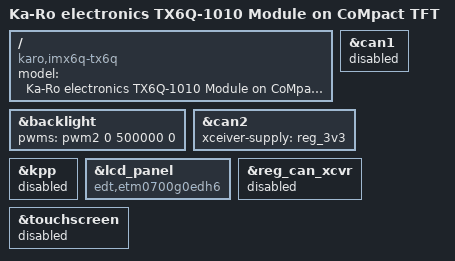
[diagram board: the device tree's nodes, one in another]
// SPDX-License-Identifier: (GPL-2.0-only OR MIT)
/*
 * Copyright 2014-2017 Lothar Waßmann <LW@KARO-electronics.de>
 */

/dts-v1/;
#include "imx6q.dtsi"
#include "imx6qdl-tx6.dtsi"
#include "imx6qdl-tx6-lcd.dtsi"

/ {
	model = "Ka-Ro electronics TX6Q-1010 Module on CoMpact TFT";
	compatible = "karo,imx6q-tx6q", "fsl,imx6q";
};

&backlight {
	pwms = <&pwm2 0 500000 0>;
};

&can1 {
	status = "disabled";
};

&can2 {
	xceiver-supply = <&reg_3v3>;
};

&kpp {
	status = "disabled";
};

&lcd_panel {
	compatible = "edt,etm0700g0edh6";
};

&reg_can_xcvr {
	status = "disabled";
};

&touchscreen {
	status = "disabled";
};
